# EFM32GG11B510F2048GQ100 register map
File version: 4.0.0
CPU: CM4 r0p1, little endian, MPU, FPU, 3 interrupt priority bits
Registers are 32-bit, read-write, reset 0x0 unless marked. A register's access mark holds for its fields unless they carry their own. Offsets are from the block's base; [hi:lo] are bit positions; {n}, {i} and the like mark numbered series.

## LDMA
Base 0x40002000
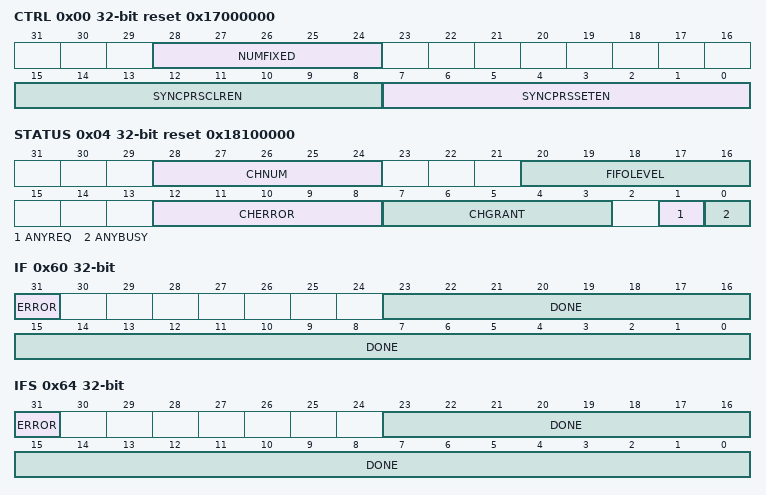
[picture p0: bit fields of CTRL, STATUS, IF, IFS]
0x00 CTRL reset 0x17000000 — DMA Control Register
  [28:24] NUMFIXED — Number of Fixed Priority Channels
  [15:8] SYNCPRSCLREN — Synchronization PRS Clear Enable
  [7:0] SYNCPRSSETEN — Synchronization PRS Set Enable
0x04 STATUS ro reset 0x18100000 — DMA Status Register
  [28:24] CHNUM — Number of Channels
  [20:16] FIFOLEVEL
  [12:8] CHERROR — Errant Channel Number
  [7:3] CHGRANT — Granted Channel Number
  [1] ANYREQ — Any DMA Channel Request Pending
  [0] ANYBUSY — Any DMA Channel Busy
0x08 SYNC — DMA Synchronization Trigger Register (Single-Cycle RMW)
  [7:0] SYNCTRIG — Synchronization Trigger
0x20 CHEN — DMA Channel Enable Register (Single-Cycle RMW)
  [23:0] CHEN — Channel Enables
0x24 CHBUSY ro — DMA Channel Busy Register
  [23:0] BUSY — Channels Busy
0x28 CHDONE — DMA Channel Linking Done Register (Single-Cycle RMW)
  [23:0] CHDONE — DMA Channel Linking or Done
0x2C DBGHALT — DMA Channel Debug Halt Register
  [23:0] DBGHALT — DMA Debug Halt
0x30 SWREQ wo — DMA Channel Software Transfer Request Register
  [23:0] SWREQ — Software Transfer Requests
0x34 REQDIS — DMA Channel Request Disable Register
  [23:0] REQDIS — DMA Request Disables
0x38 REQPEND ro — DMA Channel Requests Pending Register
  [23:0] REQPEND — DMA Requests Pending
0x3C LINKLOAD wo — DMA Channel Link Load Register
  [23:0] LINKLOAD — DMA Link Loads
0x40 REQCLEAR wo — DMA Channel Request Clear Register
  [23:0] REQCLEAR — DMA Request Clear
0x60 IF ro — Interrupt Flag Register
  [31] ERROR — Transfer Error Interrupt Flag
  [23:0] DONE — DMA Structure Operation Done Interrupt Flag
0x64 IFS wo — Interrupt Flag Set Register
  [31] ERROR — Set ERROR Interrupt Flag
  [23:0] DONE — Set DONE Interrupt Flag
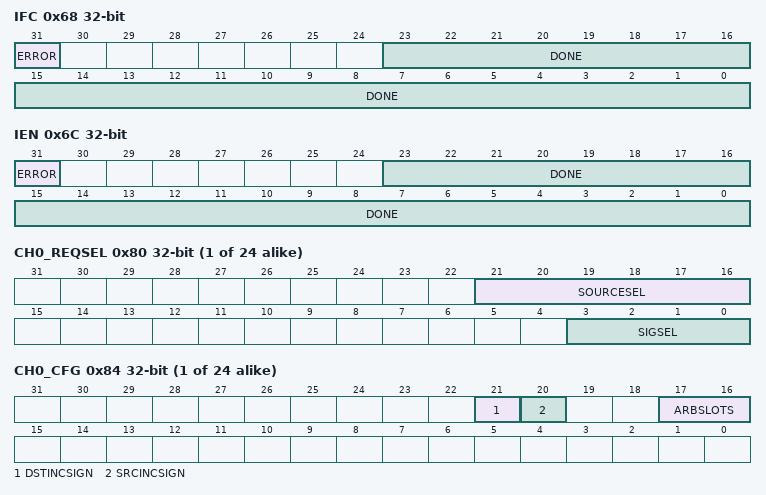
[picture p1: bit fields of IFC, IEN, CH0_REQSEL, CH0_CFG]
0x68 IFC wo — Interrupt Flag Clear Register
  [31] ERROR — Clear ERROR Interrupt Flag
  [23:0] DONE — Clear DONE Interrupt Flag
0x6C IEN — Interrupt Enable Register
  [31] ERROR — ERROR Interrupt Enable
  [23:0] DONE — DONE Interrupt Enable
{0x80+0x30*i} CH{i}_REQSEL (i=0..23) — Channel Peripheral Request Select Register
  [21:16] SOURCESEL — Source Select
    0=NONE (No source selected); 1=PRS (Peripheral Reflex System); 8=ADC0 (Analog to Digital Converter 0); 9=ADC1 (Analog to Digital Converter 0); 10=VDAC0 (Digital to Analog Converter 0); {v}=USART{v-12} (Universal Synchronous/Asynchronous Receiver/Transmitter {v-12}) (v=12..17); 18=UART0 (Universal Asynchronous Receiver/Transmitter 0); 19=UART1 (Universal Asynchronous Receiver/Transmitter 1); 20=LEUART0 (Low Energy UART 0); 21=LEUART1 (Low Energy UART 1); 22=I2C0; 23=I2C1; 24=I2C2; {v}=TIMER{v-25} (v=25..31); 32=WTIMER0 (Wide Timer 0); 33=WTIMER1 (Wide Timer 0); 34=WTIMER2 (Wide Timer 2); 35=WTIMER3 (Wide Timer 3); 48=MSC (Memory System Controller); 49=CRYPTO0 (Advanced Encryption Standard Accelerator); 50=EBI (External Bus Interface); 61=CSEN (Capacitive touch sense module); 62=LESENSE (Low Energy Sensor Interface)
  [3:0] SIGSEL — Signal Select
{0x84+0x30*i} CH{i}_CFG (i=0..23) — Channel Configuration Register
  [21] DSTINCSIGN — Destination Address Increment Sign
  [20] SRCINCSIGN — Source Address Increment Sign
  [17:16] ARBSLOTS — Arbitration Slot Number Select
    0=ONE (One arbitration slot selected); 1=TWO (Two arbitration slots selected); 2=FOUR (Four arbitration slots selected); 3=EIGHT (Eight arbitration slots selected)
{0x88+0x30*i} CH{i}_LOOP (i=0..23) — Channel Loop Counter Register
  [7:0] LOOPCNT — Linked Structure Sequence Loop Counter
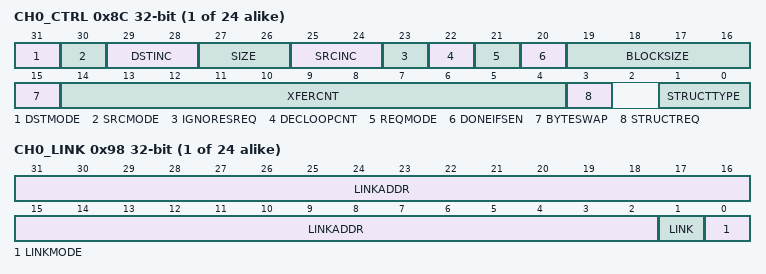
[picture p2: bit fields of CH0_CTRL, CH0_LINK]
{0x8C+0x30*i} CH{i}_CTRL (i=0..23) — Channel Descriptor Control Word Register
  [31] DSTMODE ro — Destination Addressing Mode
  [30] SRCMODE ro — Source Addressing Mode
  [29:28] DSTINC — Destination Address Increment Size
    0=ONE (Increment destination address by one unit data size after each write); 1=TWO (Increment destination address by two unit data sizes after each write); 2=FOUR (Increment destination address by four unit data sizes after each write); 3=NONE (Do not increment the destination address. Writes are made to a fixed destination address, for example writing to a FIFO.)
  [27:26] SIZE — Unit Data Transfer Size
    0=BYTE (Each unit transfer is a byte); 1=HALFWORD (Each unit transfer is a half-word); 2=WORD (Each unit transfer is a word)
  [25:24] SRCINC — Source Address Increment Size
    0=ONE (Increment source address by one unit data size after each read); 1=TWO (Increment source address by two unit data sizes after each read); 2=FOUR (Increment source address by four unit data sizes after each read); 3=NONE (Do not increment the source address. In this mode reads are made from a fixed source address, for example reading FIFO.)
  [23] IGNORESREQ
  [22] DECLOOPCNT — Decrement Loop Count
  [21] REQMODE — DMA Request Transfer Mode Select
  [20] DONEIFSEN — DMA Operation Done Interrupt Flag Set Enable
  [19:16] BLOCKSIZE — Block Transfer Size
    0=UNIT1 (One unit transfer per arbitration); 1=UNIT2 (Two unit transfers per arbitration); 2=UNIT3 (Three unit transfers per arbitration); 3=UNIT4 (Four unit transfers per arbitration); 4=UNIT6 (Six unit transfers per arbitration); 5=UNIT8 (Eight unit transfers per arbitration); 7=UNIT16 (Sixteen unit transfers per arbitration); 9=UNIT32 (32 unit transfers per arbitration); 10=UNIT64 (64 unit transfers per arbitration); 11=UNIT128 (128 unit transfers per arbitration); 12=UNIT256 (256 unit transfers per arbitration); 13=UNIT512 (512 unit transfers per arbitration); 14=UNIT1024 (1024 unit transfers per arbitration); 15=ALL (Transfer all units as specified by the XFRCNT field)
  [15] BYTESWAP — Endian Byte Swap
  [14:4] XFERCNT — DMA Unit Data Transfer Count
  [3] STRUCTREQ wo — Structure DMA Transfer Request
  [1:0] STRUCTTYPE ro — DMA Structure Type
    0=TRANSFER (DMA transfer structure type selected.); 1=SYNCHRONIZE (Synchronization structure type selected.); 2=WRITE (Write immediate value structure type selected.)
{0x90+0x30*i} CH{i}_SRC (i=0..23) — Channel Descriptor Source Data Address Register
  [31:0] SRCADDR — Source Data Address
{0x94+0x30*i} CH{i}_DST (i=0..23) — Channel Descriptor Destination Data Address Register
  [31:0] DSTADDR — Destination Data Address
{0x98+0x30*i} CH{i}_LINK (i=0..23) — Channel Descriptor Link Structure Address Register
  [31:2] LINKADDR — Link Structure Address
  [1] LINK — Link Next Structure
  [0] LINKMODE ro — Link Structure Addressing Mode

## Notices in the file
# License
Copyright 2021 Silicon Laboratories Inc. www.silabs.com
SPDX-License-Identifier: Zlib
The licensor of this software is Silicon Laboratories Inc.
This software is provided 'as-is', without any express or implied
warranty. In no event will the authors be held liable for any damages
arising from the use of this software.
Permission is granted to anyone to use this software for any purpose,
including commercial applications, and to alter it and redistribute it
freely, subject to the following restrictions:
1. The origin of this software must not be misrepresented; you must not
claim that you wrote the original software. If you use this software
in a product, an acknowledgment in the product documentation would be
appreciated but is not required.
2. Altered source versions must be plainly marked as such, and must not be
misrepresented as being the original software.
3. This notice may not be removed or altered from any source distribution.
